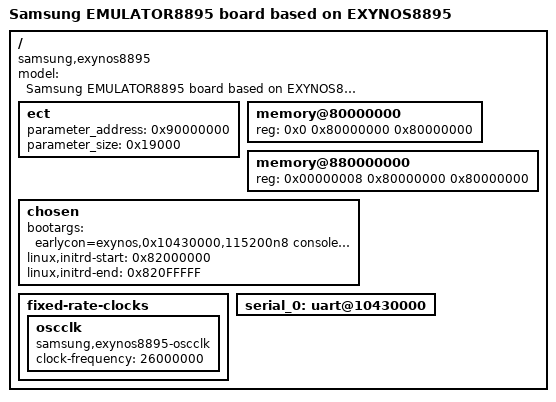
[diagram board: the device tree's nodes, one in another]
/*
 * SAMSUNG EXYNOS8895 board device tree source
 *
 * Copyright (c) 2016 Samsung Electronics Co., Ltd.
 *		http://www.samsung.com
 *
 * This program is free software; you can redistribute it and/or modify
 * it under the terms of the GNU General Public License version 2 as
 * published by the Free Software Foundation.
*/

/dts-v1/;
#include "emulator8895.dtsi"
#include "exynos8895-rmem.dtsi"

/ {
	model = "Samsung EMULATOR8895 board based on EXYNOS8895";
	compatible = "samsung,exynos8895", "samsung,EMULATOR8895";

	ect {
		parameter_address = <0x90000000>;
		parameter_size = <0x19000>;
	};

	memory@80000000 {
		device_type = "memory";
		reg = <0x0 0x80000000 0x80000000>;
	};

	memory@880000000 {
		device_type = "memory";
		reg = <0x00000008 0x80000000 0x80000000>;
	};

	chosen {
		//bootargs = "console=ttySAC0,115200 root=/dev/ram0 clk_ignore_unused ess_setup=0x86000000 androidboot.hardware=samsungexynos8895 androidboot.selinux=disabled androidboot.debug_level=0x4948";
		bootargs = "earlycon=exynos,0x10430000,115200n8 console=ttySAC0,115200 root=/dev/ram0 rw ramdisk=8192 initrd=0x82000000,8M init=/linuxrc mem=768M clk_ignore_unused ess_setup=0x86000000";
		linux,initrd-start = <0x82000000>;
		linux,initrd-end = <0x820FFFFF>;
	};

	fixed-rate-clocks {
		oscclk {
			compatible = "samsung,exynos8895-oscclk";
			clock-frequency = <26000000>;
		};
	};

	serial_0: uart@10430000 {
		status = "okay";
	};
};

